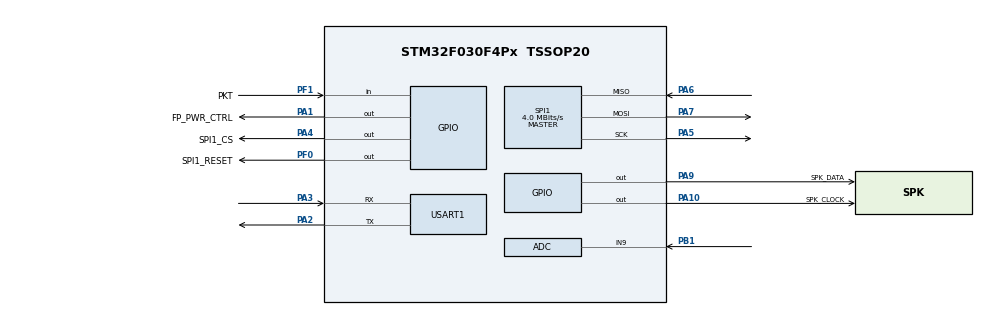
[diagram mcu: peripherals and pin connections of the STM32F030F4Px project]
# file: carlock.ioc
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Mcu.Family=STM32F0
Mcu.Name=STM32F030F4Px
Mcu.Package=TSSOP20
PA0.GPIO_Label=FP_INT
PA0.Mode=SYS_WakeUp0
PA0.Signal=SYS_WKUP1
PA1.GPIO_Label=FP_PWR_CTRL
PA1.Signal=GPIO_Output
PA10.GPIO_Label=SPK_CLOCK
PA10.Signal=GPIO_Output
PA13.Mode=Serial_Wire
PA13.Signal=SYS_SWDIO
PA14.Mode=Serial_Wire
PA14.Signal=SYS_SWCLK
PA2.Mode=Asynchronous
PA2.Signal=USART1_TX
PA3.Mode=Asynchronous
PA3.Signal=USART1_RX
PA4.GPIO_Label=SPI1_CS
PA4.Signal=GPIO_Output
PA5.Mode=Full_Duplex_Master
PA5.Signal=SPI1_SCK
PA6.Mode=Full_Duplex_Master
PA6.Signal=SPI1_MISO
PA7.Mode=Full_Duplex_Master
PA7.Signal=SPI1_MOSI
PA9.GPIO_Label=SPK_DATA
PA9.Signal=GPIO_Output
PB1.Mode=IN9
PB1.Signal=ADC_IN9
PF0-OSC_IN.GPIO_Label=SPI1_RESET
PF0-OSC_IN.Signal=GPIO_Output
PF1-OSC_OUT.GPIO_Label=PKT
PF1-OSC_OUT.Signal=GPIO_Input
ProjectManager.HeapSize=0x200
ProjectManager.StackSize=0x400
ProjectManager.TargetToolchain=MDK-ARM V5
SPI1.CalculateBaudRate=4.0 MBits/s
SPI1.Direction=SPI_DIRECTION_2LINES
SPI1.Mode=SPI_MODE_MASTER
SPI1.VirtualType=VM_MASTER
USART1.VirtualMode-Asynchronous=VM_ASYNC
board=custom

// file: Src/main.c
/**
  ******************************************************************************
  * @file           : main.c
  * @brief          : Main program body
  ******************************************************************************
  ** This notice applies to any and all portions of this file
  * that are not between comment pairs USER CODE BEGIN and
  * USER CODE END. Other portions of this file, whether
  * inserted by the user or by software development tools
  * are owned by their respective copyright owners.
  *
  * COPYRIGHT(c) 2018 STMicroelectronics
  *
  * Redistribution and use in source and binary forms, with or without modification,
  * are permitted provided that the following conditions are met:
  *   1. Redistributions of source code must retain the above copyright notice,
  *      this list of conditions and the following disclaimer.
  *   2. Redistributions in binary form must reproduce the above copyright notice,
  *      this list of conditions and the following disclaimer in the documentation
  *      and/or other materials provided with the distribution.
  *   3. Neither the name of STMicroelectronics nor the names of its contributors
  *      may be used to endorse or promote products derived from this software
  *      without specific prior written permission.
  *
  * THIS SOFTWARE IS PROVIDED BY THE COPYRIGHT HOLDERS AND CONTRIBUTORS "AS IS"
  * AND ANY EXPRESS OR IMPLIED WARRANTIES, INCLUDING, BUT NOT LIMITED TO, THE
  * IMPLIED WARRANTIES OF MERCHANTABILITY AND FITNESS FOR A PARTICULAR PURPOSE ARE
  * DISCLAIMED. IN NO EVENT SHALL THE COPYRIGHT HOLDER OR CONTRIBUTORS BE LIABLE
  * FOR ANY DIRECT, INDIRECT, INCIDENTAL, SPECIAL, EXEMPLARY, OR CONSEQUENTIAL
  * DAMAGES (INCLUDING, BUT NOT LIMITED TO, PROCUREMENT OF SUBSTITUTE GOODS OR
  * SERVICES; LOSS OF USE, DATA, OR PROFITS; OR BUSINESS INTERRUPTION) HOWEVER
  * CAUSED AND ON ANY THEORY OF LIABILITY, WHETHER IN CONTRACT, STRICT LIABILITY,
  * OR TORT (INCLUDING NEGLIGENCE OR OTHERWISE) ARISING IN ANY WAY OUT OF THE USE
  * OF THIS SOFTWARE, EVEN IF ADVISED OF THE POSSIBILITY OF SUCH DAMAGE.
  *
  ******************************************************************************
  */
#include "main.h"
#include "stm32f0xx_hal.h"
#include "adc.h"
#include "spi.h"
#include "usart.h"
#include "gpio.h"
#include "LT8920.h"

/* USER CODE BEGIN Includes */
uint32_t timeout_ms =0;
uint8_t TxBuffer[2]={0x55,0x66};
/* USER CODE END Includes */

/* USER CODE BEGIN PV */
/* Private variables ---------------------------------------------------------*/

/* USER CODE END PV */

void SystemClock_Config(void);

/* USER CODE BEGIN PFP */
/* Private function prototypes -----------------------------------------------*/

/* USER CODE END PFP */

int fputc(int ch,FILE *f)
{
    uint8_t temp[1]={ch};
    return HAL_UART_Transmit(&huart1,temp,1,2);
}

int main(void)
{
  /* USER CODE BEGIN 1 */
  uint32_t j;
  /* USER CODE END 1 */

  /* MCU Configuration----------------------------------------------------------*/

  /* Reset of all peripherals, Initializes the Flash interface and the Systick. */
  HAL_Init();

  /* Configure the system clock */
  SystemClock_Config();

  /* Initialize all configured peripherals */
  MX_GPIO_Init();
	SPI_LT8920_Init();
  MX_ADC_Init();
  MX_SPI1_Init();
  MX_USART1_UART_Init();
  /* USER CODE BEGIN 2 */
	LT8900_Init();
  /* USER CODE END 2 */
	printf("hello STM32F030F4\r\n");
	SPI_ReadReg(40);
	printf(" %02x", RegH);
	printf(" %02x", RegL);
  /* Infinite loop */
  while (1)
  {
				SPI_WriteReg(7, 0x00, 0x00);      //????
        SPI_WriteReg(52, 0x80, 0x80);     //???????FIFO??
        //SPI_WriteReg(50, 2,0);          //??????
        SPI_WriteReg(50, 2,0);
        SPI_WriteReg(50, TxBuffer[0],TxBuffer[1]);
        SPI_WriteReg(7, 0x01, 0x00);   //??
        j = 10000; //
        while(LT8920_PKT_IN == 0) //??????
        {
            j --;
            delay_us(10);
            if(j == 0)
            break;
        }
        SPI_ReadReg(52);//??????????????,REG52<13:8>??0
        if((RegH& 0x3F)==0)//???????????????LED
        {

        }
  }

}

void SystemClock_Config(void)
{

  RCC_OscInitTypeDef RCC_OscInitStruct;
  RCC_ClkInitTypeDef RCC_ClkInitStruct;
  RCC_PeriphCLKInitTypeDef PeriphClkInit;

    /**Initializes the CPU, AHB and APB busses clocks
    */
  RCC_OscInitStruct.OscillatorType = RCC_OSCILLATORTYPE_HSI|RCC_OSCILLATORTYPE_HSI14;
  RCC_OscInitStruct.HSIState = RCC_HSI_ON;
  RCC_OscInitStruct.HSI14State = RCC_HSI14_ON;
  RCC_OscInitStruct.HSICalibrationValue = 16;
  RCC_OscInitStruct.HSI14CalibrationValue = 16;
  RCC_OscInitStruct.PLL.PLLState = RCC_PLL_NONE;
  if (HAL_RCC_OscConfig(&RCC_OscInitStruct) != HAL_OK)
  {
    _Error_Handler(__FILE__, __LINE__);
  }

    /**Initializes the CPU, AHB and APB busses clocks
    */
  RCC_ClkInitStruct.ClockType = RCC_CLOCKTYPE_HCLK|RCC_CLOCKTYPE_SYSCLK
                              |RCC_CLOCKTYPE_PCLK1;
  RCC_ClkInitStruct.SYSCLKSource = RCC_SYSCLKSOURCE_HSI;
  RCC_ClkInitStruct.AHBCLKDivider = RCC_SYSCLK_DIV1;
  RCC_ClkInitStruct.APB1CLKDivider = RCC_HCLK_DIV1;

  if (HAL_RCC_ClockConfig(&RCC_ClkInitStruct, FLASH_LATENCY_0) != HAL_OK)
  {
    _Error_Handler(__FILE__, __LINE__);
  }

  PeriphClkInit.PeriphClockSelection = RCC_PERIPHCLK_USART1;
  PeriphClkInit.Usart1ClockSelection = RCC_USART1CLKSOURCE_PCLK1;
  if (HAL_RCCEx_PeriphCLKConfig(&PeriphClkInit) != HAL_OK)
  {
    _Error_Handler(__FILE__, __LINE__);
  }

    /**Configure the Systick interrupt time
    */
  HAL_SYSTICK_Config(HAL_RCC_GetHCLKFreq()/1000);

    /**Configure the Systick
    */
  HAL_SYSTICK_CLKSourceConfig(SYSTICK_CLKSOURCE_HCLK);

  /* SysTick_IRQn interrupt configuration */
  HAL_NVIC_SetPriority(SysTick_IRQn, 0, 0);
}

void _Error_Handler(char *file, int line)
{
  while(1)
  {
  }
}

/************************ (C) COPYRIGHT STMicroelectronics *****END OF FILE****/
